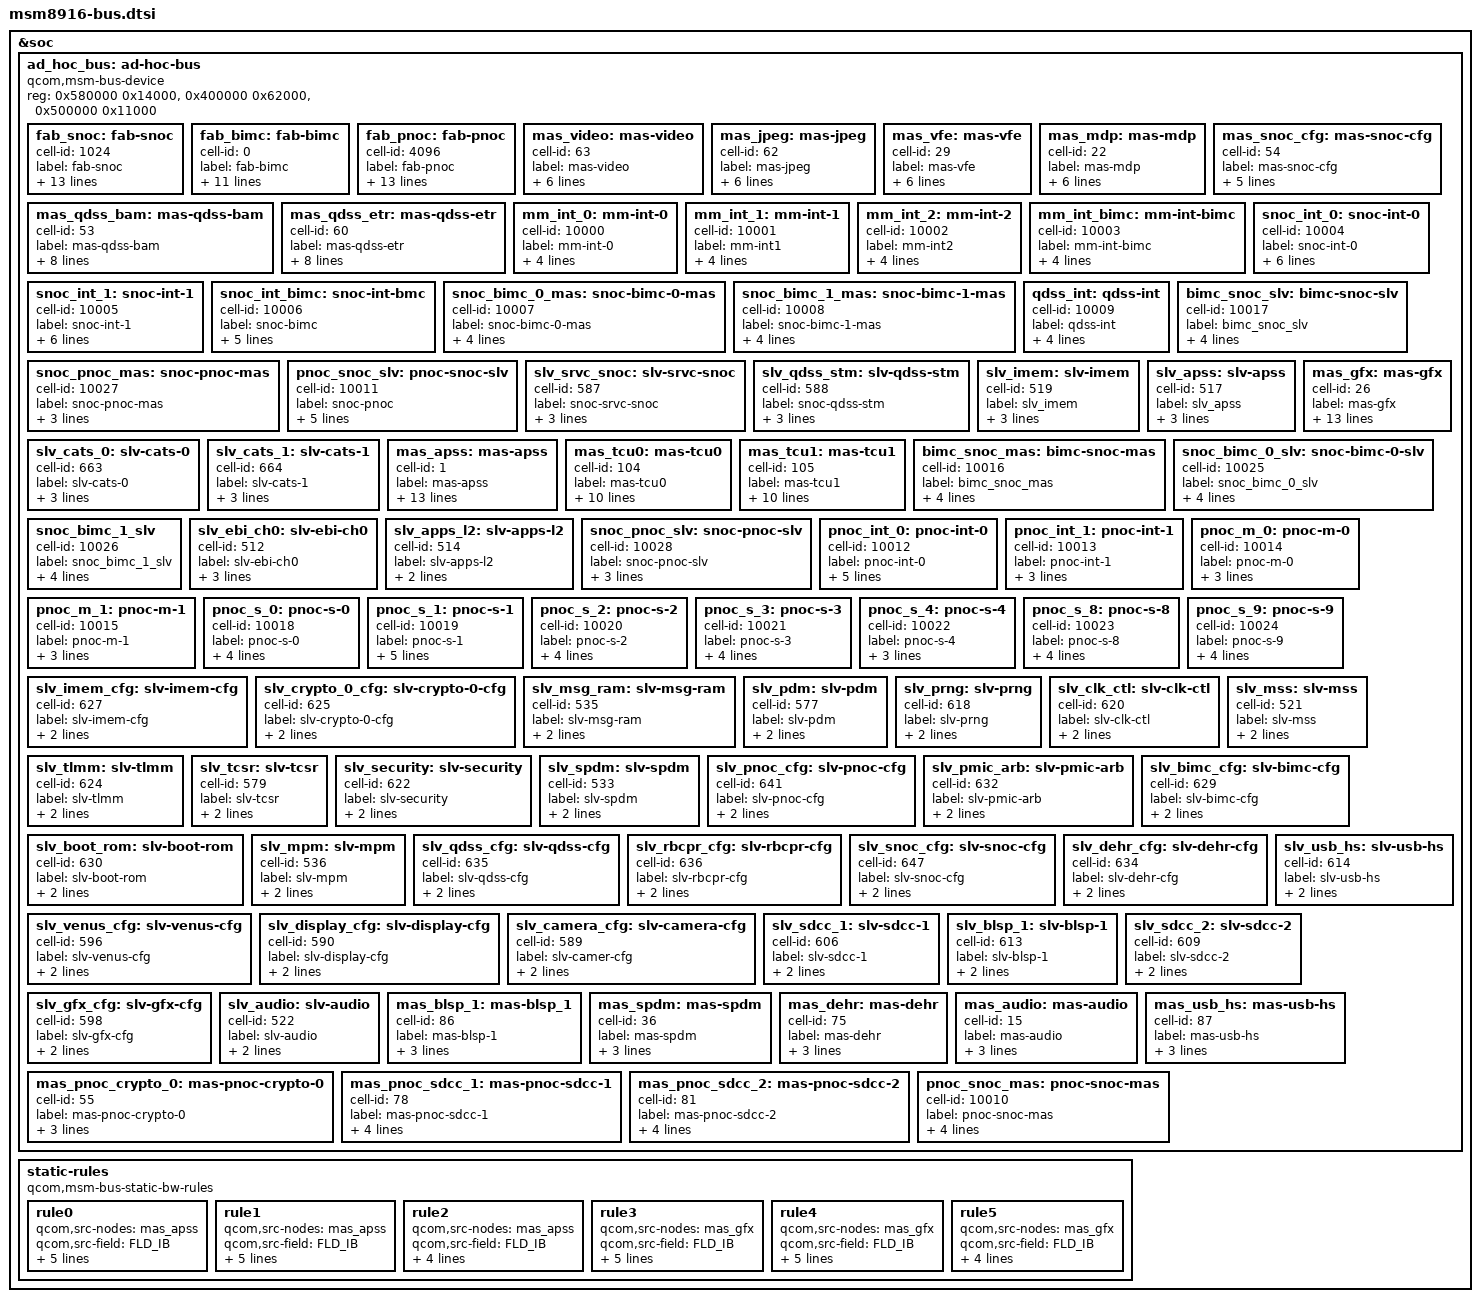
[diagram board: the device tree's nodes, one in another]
/* Copyright (c) 2014, The Linux Foundation. All rights reserved.
 *
 * This program is free software; you can redistribute it and/or modify
 * it under the terms of the GNU General Public License version 2 and
 * only version 2 as published by the Free Software Foundation.
 *
 * This program is distributed in the hope that it will be useful,
 * but WITHOUT ANY WARRANTY; without even the implied warranty of
 * MERCHANTABILITY or FITNESS FOR A PARTICULAR PURPOSE.  See the
 * GNU General Public License for more details.
 */

#include <dt-bindings/msm/msm-bus-rule-ops.h>

&soc {
	ad_hoc_bus: ad-hoc-bus { };

	static-rules {
		compatible = "qcom,msm-bus-static-bw-rules";

		rule0 {
			qcom,src-nodes = <&mas_apss>;
			qcom,src-field = <FLD_IB>;
			qcom,src-op = <OP_LE>;
			qcom,thresh = <1600000>;
			qcom,mode = <THROTTLE_ON>;
			qcom,dest-node = <&mas_apss>;
			qcom,dest-bw = <600000>;
		};


		rule1 {
			qcom,src-nodes = <&mas_apss>;
			qcom,src-field = <FLD_IB>;
			qcom,src-op = <OP_LE>;
			qcom,thresh = <3200000>;
			qcom,mode = <THROTTLE_ON>;
			qcom,dest-node = <&mas_apss>;
			qcom,dest-bw = <1200000>;
		};

		rule2 {
			qcom,src-nodes = <&mas_apss>;
			qcom,src-field = <FLD_IB>;
			qcom,src-op = <OP_GT>;
			qcom,thresh = <3200000>;
			qcom,mode = <THROTTLE_OFF>;
			qcom,dest-node = <&mas_apss>;
		};

		rule3 {
			qcom,src-nodes = <&mas_gfx>;
			qcom,src-field = <FLD_IB>;
			qcom,src-op = <OP_LE>;
			qcom,thresh = <1600000>;
			qcom,mode = <THROTTLE_ON>;
			qcom,dest-node = <&mas_gfx>;
			qcom,dest-bw = <600000>;
		};

		rule4 {
			qcom,src-nodes = <&mas_gfx>;
			qcom,src-field = <FLD_IB>;
			qcom,src-op = <OP_LE>;
			qcom,thresh = <3200000>;
			qcom,mode = <THROTTLE_ON>;
			qcom,dest-node = <&mas_gfx>;
			qcom,dest-bw = <1200000>;
		};

		rule5 {
			qcom,src-nodes = <&mas_gfx>;
			qcom,src-field = <FLD_IB>;
			qcom,src-op = <OP_GT>;
			qcom,thresh = <3200000>;
			qcom,mode = <THROTTLE_OFF>;
			qcom,dest-node = <&mas_gfx>;
		};
	};
};

&ad_hoc_bus {
	compatible = "qcom,msm-bus-device";
	reg = <0x580000 0x14000>,
		<0x400000 0x62000>,
		<0x500000 0x11000>;
	reg-names = "snoc-base", "bimc-base", "pnoc-base";

	fab_snoc: fab-snoc {
		cell-id = <1024>;
		label = "fab-snoc";
		qcom,fab-dev;
		qcom,base-name = "snoc-base";
		qcom,base-offset = <0x7000>;
		qcom,qos-off = <0x1000>;
		qcom,bus-type = <1>;
		clock-names = "bus_clk", "bus_a_clk";
		clocks = <&clock_rpm  clk_snoc_msmbus_clk>,
                      <&clock_rpm  clk_snoc_msmbus_a_clk>;

		coresight-id = <50>;
		coresight-name = "coresight-snoc";
		coresight-nr-inports = <0>;
		coresight-outports = <0>;
		coresight-child-list = <&funnel_in2>;
		coresight-child-ports = <5>;
	};

	fab_bimc: fab-bimc {
		cell-id = <0>;
		label = "fab-bimc";
		qcom,fab-dev;
		qcom,base-name = "bimc-base";
		qcom,bus-type = <2>;
		clock-names = "bus_clk", "bus_a_clk";
		clocks = <&clock_rpm  clk_bimc_msmbus_clk>,
                      <&clock_rpm  clk_bimc_msmbus_a_clk>;

		coresight-id = <55>;
		coresight-name = "coresight-bimc";
		coresight-nr-inports = <0>;
		coresight-outports = <0>;
		coresight-child-list = <&funnel_in2>;
		coresight-child-ports = <3>;
	};

	fab_pnoc: fab-pnoc {
		cell-id = <4096>;
		label = "fab-pnoc";
		qcom,fab-dev;
		qcom,base-name = "pnoc-base";
		qcom,base-offset = <0x7000>;
		qcom,qos-delta = <0x1000>;
		qcom,bus-type = <1>;
		clock-names = "bus_clk", "bus_a_clk";
		clocks = <&clock_rpm  clk_pcnoc_msmbus_clk>,
                      <&clock_rpm  clk_pcnoc_msmbus_a_clk>;

		coresight-id = <54>;
		coresight-name = "coresight-pnoc";
		coresight-nr-inports = <0>;
		coresight-outports = <0>;
		coresight-child-list = <&funnel_in2>;
		coresight-child-ports = <6>;
	};

	/* SNOC Devices */
	mas_video: mas-video {
		cell-id = <63>;
		label = "mas-video";
		qcom,qport = <8>;
		qcom,ap-owned;
		qcom,connections = <&mm_int_0 &mm_int_2>;
		qcom,bus-dev = <&fab_snoc>;
		qcom,qos-mode = "bypass";
		qcom,buswidth = <16>;
	};

	mas_jpeg: mas-jpeg {
		cell-id = <62>;
		label = "mas-jpeg";
		qcom,ap-owned;
		qcom,qport = <6>;
		qcom,connections = <&mm_int_0 &mm_int_2>;
		qcom,bus-dev = <&fab_snoc>;
		qcom,qos-mode = "bypass";
		qcom,buswidth = <16>;
	};

	mas_vfe: mas-vfe {
		cell-id = <29>;
		label = "mas-vfe";
		qcom,ap-owned;
		qcom,qport = <9>;
		qcom,connections = <&mm_int_1 &mm_int_2>;
		qcom,bus-dev = <&fab_snoc>;
		qcom,qos-mode = "bypass";
		qcom,buswidth = <16>;
	};

	mas_mdp: mas-mdp {
		cell-id = <22>;
		label = "mas-mdp";
		qcom,ap-owned;
		qcom,connections = <&mm_int_0 &mm_int_2>;
		qcom,qport = <7>;
		qcom,bus-dev = <&fab_snoc>;
		qcom,qos-mode = "bypass";
		qcom,buswidth = <16>;
	};

	mas_qdss_bam: mas-qdss-bam {
		cell-id = <53>;
		label = "mas-qdss-bam";
		qcom,connections = <&qdss_int>;
		qcom,qport = <11>;
		qcom,bus-dev = <&fab_snoc>;
		qom,buswidth = <4>;
		qcom,ap-owned;
		qcom,qos-mode = "fixed";
		qcom,prio1 = <1>;
		qcom,prio0 = <1>;
	};

	mas_snoc_cfg: mas-snoc-cfg {
		cell-id = <54>;
		label = "mas-snoc-cfg";
		qcom,connections = <&qdss_int>;
		qcom,bus-dev = <&fab_snoc>;
		qcom,qos-mode = "bypass";
		qom,buswidth = <4>;
		qcom,mas-rpm-id = <20>;
	};

	mas_qdss_etr: mas-qdss-etr {
		cell-id = <60>;
		label = "mas-qdss-etr";
		qcom,connections = <&qdss_int>;
		qcom,qport = <10>;
		qcom,bus-dev = <&fab_snoc>;
		qcom,qos-mode = "fixed";
		qcom,prio1 = <1>;
		qcom,prio0 = <1>;
		qom,buswidth = <8>;
		qcom,ap-owned;
	};

	mm_int_0: mm-int-0 {
		cell-id = <10000>;
		label = "mm-int-0";
		qcom,ap-owned;
		qcom,connections = <&mm_int_bimc>;
		qcom,bus-dev = <&fab_snoc>;
		qcom,buswidth = <16>;
	};

	mm_int_1: mm-int-1 {
		cell-id = <10001>;
		label = "mm-int1";
		qcom,ap-owned;
		qcom,connections = <&mm_int_bimc>;
		qcom,bus-dev = <&fab_snoc>;
		qcom,buswidth = <16>;
	};

	mm_int_2: mm-int-2 {
		cell-id = <10002>;
		label = "mm-int2";
		qcom,ap-owned;
		qcom,connections = <&snoc_int_0>;
		qcom,bus-dev = <&fab_snoc>;
		qcom,buswidth = <16>;
	};

	mm_int_bimc: mm-int-bimc {
		cell-id = <10003>;
		label = "mm-int-bimc";
		qcom,ap-owned;
		qcom,connections = <&snoc_bimc_1_mas>;
		qcom,bus-dev = <&fab_snoc>;
		qcom,buswidth = <16>;
	};

	snoc_int_0: snoc-int-0 {
		cell-id = <10004>;
		label = "snoc-int-0";
		qcom,connections = <&slv_qdss_stm &slv_imem &snoc_pnoc_mas>;
		qcom,bus-dev = <&fab_snoc>;
		qcom,mas-rpm-id = <99>;
		qcom,slv-rpm-id = <130>;
		qcom,buswidth = <8>;
	};

	snoc_int_1: snoc-int-1 {
		cell-id = <10005>;
		label = "snoc-int-1";
		qcom,connections = <&slv_apss &slv_cats_0 &slv_cats_1>;
		qcom,bus-dev = <&fab_snoc>;
		qcom,mas-rpm-id = <100>;
		qcom,slv-rpm-id = <131>;
		qcom,buswidth = <8>;
	};

	snoc_int_bimc: snoc-int-bmc {
		cell-id = <10006>;
		label = "snoc-bimc";
		qcom,connections = <&snoc_bimc_0_mas>;
		qcom,bus-dev = <&fab_snoc>;
		qcom,mas-rpm-id = <101>;
		qcom,slv-rpm-id = <132>;
		qcom,buswidth = <8>;
	};

	snoc_bimc_0_mas: snoc-bimc-0-mas {
		cell-id = <10007>;
		label = "snoc-bimc-0-mas";
		qcom,connections = <&snoc_bimc_0_slv>;
		qcom,bus-dev = <&fab_snoc>;
		qcom,mas-rpm-id = <3>;
		qcom,buswidth = <8>;
	};

	snoc_bimc_1_mas: snoc-bimc-1-mas {
		cell-id = <10008>;
		label = "snoc-bimc-1-mas";
		qcom,connections = <&snoc_bimc_1_slv>;
		qcom,bus-dev = <&fab_snoc>;
		qcom,ap-owned;
		qcom,buswidth = <16>;
	};

	qdss_int: qdss-int {
		cell-id = <10009>;
		label = "qdss-int";
		qcom,ap-owned;
		qcom,connections = <&snoc_int_0 &snoc_int_bimc>;
		qcom,bus-dev = <&fab_snoc>;
		qcom,buswidth = <8>;
	};

	bimc_snoc_slv: bimc-snoc-slv {
		cell-id = <10017>;
		label = "bimc_snoc_slv";
		qcom,ap-owned;
		qcom,connections = <&snoc_int_0 &snoc_int_1>;
		qcom,bus-dev = <&fab_snoc>;
		qcom,buswidth = <8>;
	};

	snoc_pnoc_mas: snoc-pnoc-mas {
		cell-id = <10027>;
		label = "snoc-pnoc-mas";
		qcom,connections = <&snoc_pnoc_slv>;
		qcom,bus-dev = <&fab_snoc>;
		qcom,buswidth = <8>;
	};

	pnoc_snoc_slv: pnoc-snoc-slv {
		cell-id = <10011>;
		label = "snoc-pnoc";
		qcom,connections = <&snoc_int_0 &snoc_int_bimc &snoc_int_1>;
		qcom,bus-dev = <&fab_snoc>;
		qcom,slv-rpm-id = <45>;
		qcom,buswidth = <8>;
	};

	slv_srvc_snoc: slv-srvc-snoc {
		cell-id = <587>;
		label = "snoc-srvc-snoc";
		qcom,bus-dev = <&fab_snoc>;
		qcom,slv-rpm-id = <29>;
		qcom,buswidth = <8>;
	};

	slv_qdss_stm: slv-qdss-stm {
		cell-id = <588>;
		label = "snoc-qdss-stm";
		qcom,bus-dev = <&fab_snoc>;
		qcom,buswidth = <4>;
		qcom,slv-rpm-id = <30>;
	};

	slv_imem: slv-imem {
		cell-id = <519>;
		label = "slv_imem";
		qcom,bus-dev = <&fab_snoc>;
		qcom,buswidth = <8>;
		qcom,slv-rpm-id = <26>;
	};

	slv_apss: slv-apss {
		cell-id = <517>;
		label = "slv_apss";
		qcom,bus-dev = <&fab_snoc>;
		qcom,slv-rpm-id = <20>;
		qcom,buswidth = <4>;
	};

	slv_cats_0: slv-cats-0 {
		cell-id = <663>;
		label = "slv-cats-0";
		qcom,bus-dev = <&fab_snoc>;
		qcom,slv-rpm-id = <106>;
		qcom,buswidth = <16>;
	};

	slv_cats_1: slv-cats-1 {
		cell-id = <664>;
		label = "slv-cats-1";
		qcom,bus-dev = <&fab_snoc>;
		qcom,slv-rpm-id = <107>;
		qcom,buswidth = <8>;
	};

	/* BIMC nodes */
	mas_apss: mas-apss {
		cell-id = <1>;
		label = "mas-apss";
		qcom,ap-owned;
		qcom,connections = <&slv_ebi_ch0 &bimc_snoc_mas &slv_apps_l2>;
		qcom,qport = <0>;
		qcom,bus-dev = <&fab_bimc>;
		qcom,qos-mode = "fixed";
		qcom,prio-lvl = <0>;
		qcom,prio-rd = <0>;
		qcom,prio-wr = <0>;
		qcom,ws = <10000>;
		qcom,gp = <5000>;
		qcom,thmp = <50>;
		qom,buswidth = <8>;
	};

	mas_tcu0: mas-tcu0 {
		cell-id = <104>;
		label = "mas-tcu0";
		qcom,ap-owned;
		qcom,connections = <&slv_ebi_ch0 &bimc_snoc_mas &slv_apps_l2>;
		qcom,qport = <5>;
		qcom,bus-dev = <&fab_bimc>;
		qcom,qos-mode = "fixed";
		qcom,prio-lvl = <2>;
		qcom,prio-rd = <2>;
		qcom,prio-wr = <2>;
		qom,buswidth = <8>;
	};

	mas_tcu1: mas-tcu1 {
		cell-id = <105>;
		label = "mas-tcu1";
		qcom,ap-owned;
		qcom,connections = <&slv_ebi_ch0 &bimc_snoc_mas &slv_apps_l2>;
		qcom,qport = <6>;
		qcom,bus-dev = <&fab_bimc>;
		qcom,qos-mode = "fixed";
		qcom,prio-lvl = <2>;
		qcom,prio-rd = <2>;
		qcom,prio-wr = <2>;
		qom,buswidth = <8>;
	};

	mas_gfx: mas-gfx {
		cell-id = <26>;
		label = "mas-gfx";
		qcom,ap-owned;
		qcom,connections = <&slv_ebi_ch0 &bimc_snoc_mas &slv_apps_l2>;
		qcom,qport = <2>;
		qcom,bus-dev = <&fab_bimc>;
		qcom,qos-mode = "fixed";
		qcom,prio-lvl = <0>;
		qcom,prio-rd = <0>;
		qcom,prio-wr = <0>;
		qom,buswidth = <8>;
		qcom,ws = <10000>;
		qcom,gp = <5000>;
		qcom,thmp = <50>;
	};

	bimc_snoc_mas: bimc-snoc-mas {
		cell-id = <10016>;
		label = "bimc_snoc_mas";
		qcom,ap-owned;
		qcom,bus-dev = <&fab_bimc>;
		qcom,connections = <&bimc_snoc_slv>;
		qom,buswidth = <8>;
	};

	snoc_bimc_0_slv: snoc-bimc-0-slv {
		cell-id = <10025>;
		label = "snoc_bimc_0_slv";
		qcom,connections = <&slv_ebi_ch0>;
		qcom,bus-dev = <&fab_bimc>;
		qcom,slv-rpm-id = <24>;
		qom,buswidth = <8>;
	};

	snoc_bimc_1_slv: snoc_bimc_1_slv {
		cell-id = <10026>;
		label = "snoc_bimc_1_slv";
		qcom,connections = <&slv_ebi_ch0>;
		qcom,ap-owned;
		qcom,bus-dev = <&fab_bimc>;
		qom,buswidth = <8>;
	};

	slv_ebi_ch0: slv-ebi-ch0 {
		cell-id = <512>;
		label = "slv-ebi-ch0";
		qcom,bus-dev = <&fab_bimc>;
		qcom,slv-rpm-id = <0>;
		qom,buswidth = <8>;
	};

	slv_apps_l2: slv-apps-l2 {
		cell-id = <514>;
		label = "slv-apps-l2";
		qcom,bus-dev = <&fab_bimc>;
		qom,buswidth = <8>;
	};

	/* PNOC nodes */
	snoc_pnoc_slv: snoc-pnoc-slv {
		cell-id = <10028>;
		label = "snoc-pnoc-slv";
		qcom,connections = <&pnoc_int_0>;
		qcom,bus-dev = <&fab_pnoc>;
		qcom,buswidth = <8>;
	};

	pnoc_int_0: pnoc-int-0 {
		cell-id = <10012>;
		label = "pnoc-int-0";
		qcom,connections = <&pnoc_snoc_mas &pnoc_s_0 &pnoc_s_1 &pnoc_s_2
				&pnoc_s_3 &pnoc_s_4 &pnoc_s_8 &pnoc_s_9>;
		qcom,bus-dev = <&fab_pnoc>;
		qom,buswidth = <8>;
	};

	pnoc_int_1: pnoc-int-1 {
		cell-id = <10013>;
		label = "pnoc-int-1";
		qcom,connections = <&pnoc_snoc_mas>;
		qcom,bus-dev = <&fab_pnoc>;
		qom,buswidth = <8>;
	};

	pnoc_m_0: pnoc-m-0 {
		cell-id = <10014>;
		label = "pnoc-m-0";
		qcom,connections = <&pnoc_int_0>;
		qcom,bus-dev = <&fab_pnoc>;
		qom,buswidth = <8>;
	};

	pnoc_m_1: pnoc-m-1 {
		cell-id = <10015>;
		label = "pnoc-m-1";
		qcom,connections = <&pnoc_snoc_mas>;
		qcom,bus-dev = <&fab_pnoc>;
		qom,buswidth = <8>;
	};

	pnoc_s_0: pnoc-s-0 {
		cell-id = <10018>;
		label = "pnoc-s-0";
		qcom,connections = <&slv_clk_ctl &slv_tlmm &slv_tcsr
			&slv_security &slv_mss>;
		qcom,bus-dev = <&fab_pnoc>;
		qom,buswidth = <4>;
	};

	pnoc_s_1: pnoc-s-1 {
		cell-id = <10019>;
		label = "pnoc-s-1";
		qcom,connections = <&slv_imem_cfg &slv_crypto_0_cfg
				&slv_msg_ram &slv_pdm &slv_prng>;
		qcom,bus-dev = <&fab_pnoc>;
		qom,buswidth = <4>;
	};

	pnoc_s_2: pnoc-s-2 {
		cell-id = <10020>;
		label = "pnoc-s-2";
		qcom,connections = <&slv_spdm &slv_boot_rom &slv_bimc_cfg
				&slv_pnoc_cfg &slv_pmic_arb>;
		qcom,bus-dev = <&fab_pnoc>;
		qom,buswidth = <4>;
	};

	pnoc_s_3: pnoc-s-3 {
		cell-id = <10021>;
		label = "pnoc-s-3";
		qcom,connections = <&slv_mpm &slv_snoc_cfg &slv_rbcpr_cfg
				&slv_qdss_cfg &slv_dehr_cfg>;
		qcom,bus-dev = <&fab_pnoc>;
		qom,buswidth = <4>;
	};

	pnoc_s_4: pnoc-s-4 {
		cell-id = <10022>;
		label = "pnoc-s-4";
		qcom,connections = <&slv_venus_cfg &slv_camera_cfg
				&slv_display_cfg>;
		qcom,bus-dev = <&fab_pnoc>;
	};

	pnoc_s_8: pnoc-s-8 {
		cell-id = <10023>;
		label = "pnoc-s-8";
		qcom,connections = <&slv_usb_hs &slv_sdcc_1 &slv_blsp_1>;
		qcom,bus-dev = <&fab_pnoc>;
		qom,buswidth = <4>;
	};

	pnoc_s_9: pnoc-s-9 {
		cell-id = <10024>;
		label = "pnoc-s-9";
		qcom,connections = <&slv_sdcc_2 &slv_audio &slv_gfx_cfg>;
		qcom,bus-dev = <&fab_pnoc>;
		qom,buswidth = <4>;
	};

	slv_imem_cfg: slv-imem-cfg {
		cell-id = <627>;
		label = "slv-imem-cfg";
		qcom,bus-dev = <&fab_pnoc>;
		qcom,buswidth = <4>;
	};

	slv_crypto_0_cfg: slv-crypto-0-cfg {
		cell-id = <625>;
		label = "slv-crypto-0-cfg";
		qcom,bus-dev = <&fab_pnoc>;
		qcom,buswidth = <4>;
	};

	slv_msg_ram: slv-msg-ram {
		cell-id = <535>;
		label = "slv-msg-ram";
		qcom,bus-dev = <&fab_pnoc>;
		qcom,buswidth = <4>;
	};

	slv_pdm: slv-pdm {
		cell-id = <577>;
		label = "slv-pdm";
		qcom,bus-dev = <&fab_pnoc>;
		qcom,buswidth = <4>;
	};

	slv_prng: slv-prng {
		cell-id = <618>;
		label = "slv-prng";
		qcom,bus-dev = <&fab_pnoc>;
		qcom,buswidth = <4>;
	};

	slv_clk_ctl: slv-clk-ctl {
		cell-id = <620>;
		label = "slv-clk-ctl";
		qcom,bus-dev = <&fab_pnoc>;
		qcom,buswidth = <4>;
	};

	slv_mss: slv-mss {
		cell-id = <521>;
		label = "slv-mss";
		qcom,bus-dev = <&fab_pnoc>;
		qcom,buswidth = <4>;
	};

	slv_tlmm: slv-tlmm {
		cell-id = <624>;
		label = "slv-tlmm";
		qcom,bus-dev = <&fab_pnoc>;
		qcom,buswidth = <4>;
	};

	slv_tcsr: slv-tcsr {
		cell-id = <579>;
		label = "slv-tcsr";
		qcom,bus-dev = <&fab_pnoc>;
		qcom,buswidth = <4>;
	};

	slv_security: slv-security {
		cell-id = <622>;
		label = "slv-security";
		qcom,bus-dev = <&fab_pnoc>;
		qcom,buswidth = <4>;
	};

	slv_spdm: slv-spdm {
		cell-id = <533>;
		label = "slv-spdm";
		qcom,bus-dev = <&fab_pnoc>;
		qcom,buswidth = <4>;
	};

	slv_pnoc_cfg: slv-pnoc-cfg {
		cell-id = <641>;
		label = "slv-pnoc-cfg";
		qcom,bus-dev = <&fab_pnoc>;
		qcom,buswidth = <4>;
	};

	slv_pmic_arb: slv-pmic-arb {
		cell-id = <632>;
		label = "slv-pmic-arb";
		qcom,bus-dev = <&fab_pnoc>;
		qcom,buswidth = <4>;
	};

	slv_bimc_cfg: slv-bimc-cfg {
		cell-id = <629>;
		label = "slv-bimc-cfg";
		qcom,bus-dev = <&fab_pnoc>;
		qcom,buswidth = <4>;
	};

	slv_boot_rom: slv-boot-rom {
		cell-id = <630>;
		label = "slv-boot-rom";
		qcom,bus-dev = <&fab_pnoc>;
		qcom,buswidth = <4>;
	};

	slv_mpm: slv-mpm {
		cell-id = <536>;
		label = "slv-mpm";
		qcom,bus-dev = <&fab_pnoc>;
		qcom,buswidth = <4>;
	};

	slv_qdss_cfg: slv-qdss-cfg {
		cell-id = <635>;
		label = "slv-qdss-cfg";
		qcom,bus-dev = <&fab_pnoc>;
		qcom,buswidth = <4>;
	};

	slv_rbcpr_cfg: slv-rbcpr-cfg {
		cell-id = <636>;
		label = "slv-rbcpr-cfg";
		qcom,bus-dev = <&fab_pnoc>;
		qcom,buswidth = <4>;
	};

	slv_snoc_cfg: slv-snoc-cfg {
		cell-id = <647>;
		label = "slv-snoc-cfg";
		qcom,bus-dev = <&fab_pnoc>;
		qcom,buswidth = <4>;
	};

	slv_dehr_cfg: slv-dehr-cfg {
		cell-id = <634>;
		label = "slv-dehr-cfg";
		qcom,bus-dev = <&fab_pnoc>;
		qcom,buswidth = <4>;
	};

	slv_venus_cfg: slv-venus-cfg {
		cell-id = <596>;
		label = "slv-venus-cfg";
		qcom,bus-dev = <&fab_pnoc>;
		qcom,buswidth = <4>;
	};

	slv_display_cfg: slv-display-cfg {
		cell-id = <590>;
		label = "slv-display-cfg";
		qcom,bus-dev = <&fab_pnoc>;
		qcom,buswidth = <4>;
	};

	slv_camera_cfg: slv-camera-cfg {
		cell-id = <589>;
		label = "slv-camer-cfg";
		qcom,bus-dev = <&fab_pnoc>;
		qcom,buswidth = <4>;
	};

	slv_usb_hs: slv-usb-hs {
		cell-id = <614>;
		label = "slv-usb-hs";
		qcom,bus-dev = <&fab_pnoc>;
		qcom,buswidth = <4>;
	};

	slv_sdcc_1: slv-sdcc-1 {
		cell-id = <606>;
		label = "slv-sdcc-1";
		qcom,bus-dev = <&fab_pnoc>;
		qcom,buswidth = <4>;
	};

	slv_blsp_1: slv-blsp-1 {
		cell-id = <613>;
		label = "slv-blsp-1";
		qcom,bus-dev = <&fab_pnoc>;
		qcom,buswidth = <4>;
	};

	slv_sdcc_2: slv-sdcc-2 {
		cell-id = <609>;
		label = "slv-sdcc-2";
		qcom,bus-dev = <&fab_pnoc>;
		qcom,buswidth = <4>;
	};

	slv_gfx_cfg: slv-gfx-cfg {
		cell-id = <598>;
		label = "slv-gfx-cfg";
		qcom,bus-dev = <&fab_pnoc>;
		qcom,buswidth = <4>;
	};

	slv_audio: slv-audio {
		cell-id = <522>;
		label = "slv-audio";
		qcom,bus-dev = <&fab_pnoc>;
		qcom,buswidth = <4>;
	};

	mas_blsp_1: mas-blsp_1 {
		cell-id = <86>;
		label = "mas-blsp-1";
		qcom,connections = <&pnoc_m_1>;
		qcom,bus-dev = <&fab_pnoc>;
		qcom,buswidth = <4>;
	};

	mas_spdm: mas-spdm {
		cell-id = <36>;
		label = "mas-spdm";
		qcom,connections = <&pnoc_m_0>;
		qcom,bus-dev = <&fab_pnoc>;
		qcom,buswidth = <4>;
	};

	mas_dehr: mas-dehr {
		cell-id = <75>;
		label = "mas-dehr";
		qcom,connections = <&pnoc_m_0>;
		qcom,bus-dev = <&fab_pnoc>;
		qcom,buswidth = <4>;
	};

	mas_audio: mas-audio {
		cell-id = <15>;
		label = "mas-audio";
		qcom,connections = <&pnoc_m_0>;
		qcom,bus-dev = <&fab_pnoc>;
		qcom,buswidth = <4>;
	};

	mas_usb_hs: mas-usb-hs {
		cell-id = <87>;
		label = "mas-usb-hs";
		qcom,connections = <&pnoc_m_1>;
		qcom,bus-dev = <&fab_pnoc>;
		qcom,buswidth = <4>;
	};

	mas_pnoc_crypto_0: mas-pnoc-crypto-0 {
		cell-id = <55>;
		label = "mas-pnoc-crypto-0";
		qcom,connections = <&pnoc_int_1>;
		qcom,bus-dev = <&fab_pnoc>;
		qcom,buswidth = <8>;
	};

	mas_pnoc_sdcc_1: mas-pnoc-sdcc-1 {
		cell-id = <78>;
		label = "mas-pnoc-sdcc-1";
		qcom,qport = <7>;
		qcom,connections = <&pnoc_int_1>;
		qcom,bus-dev = <&fab_pnoc>;
		qcom,buswidth = <8>;
	};

	mas_pnoc_sdcc_2: mas-pnoc-sdcc-2 {
		cell-id = <81>;
		label = "mas-pnoc-sdcc-2";
		qcom,qport = <8>;
		qcom,connections = <&pnoc_int_1>;
		qcom,bus-dev = <&fab_pnoc>;
		qcom,buswidth = <8>;
	};

	pnoc_snoc_mas: pnoc-snoc-mas {
		cell-id = <10010>;
		label = "pnoc-snoc-mas";
		qcom,connections = <&pnoc_snoc_slv>;
		qcom,bus-dev = <&fab_pnoc>;
		qcom,mas-rpm-id = <29>;
		qcom,buswidth = <8>;
	};
};
